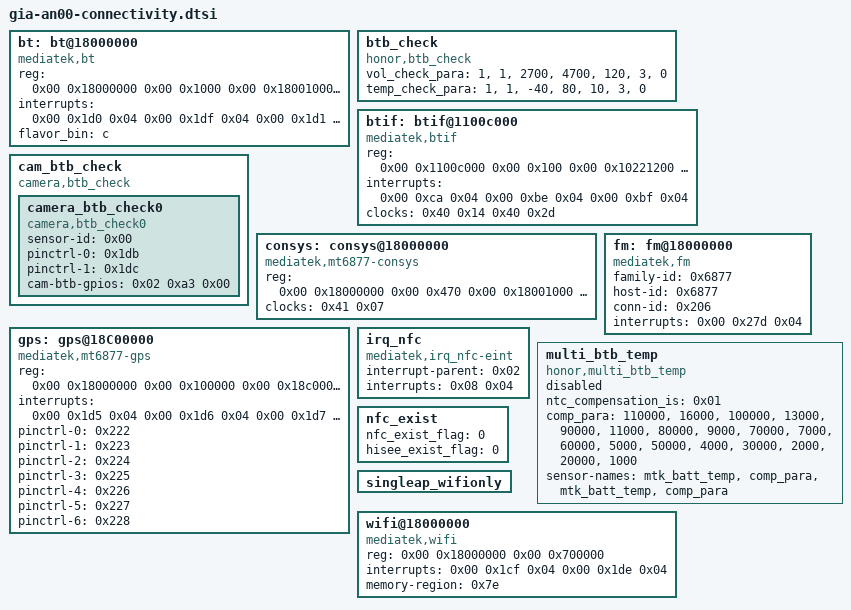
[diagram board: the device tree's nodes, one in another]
// SPDX-License-Identifier: GPL-2.0
/*
 * HONOR GIA-AN00 / MT6877V/ZA 设备树分片
 * 由实机反编译 device.dts 自动还原，节点内容保持原样
 */

/* 12 个顶层节点 */

	bt: bt@18000000 {
			compatible = "mediatek,bt";
			reg = <0x00 0x18000000 0x00 0x1000 0x00 0x18001000 0x00 0x1000 0x00 0x18050000 0x00 0x1000 0x00 0x18060000 0x00 0x1000 0x00 0x18800000 0x00 0x1000 0x00 0x18812000 0x00 0x1000 0x00 0x10001000 0x00 0x1000>;
			interrupts = <0x00 0x1d0 0x04 0x00 0x1df 0x04 0x00 0x1d1 0x04>;
			flavor_bin = "c";
			phandle = <0x34>;
		};

	btb_check: btb_check {
			compatible = "honor,btb_check";
			status = "ok";
			phandle = <0xd0>;
			vol_check_para = "1", "1", "2700", "4700", "120", "3", "0";
			temp_check_para = "1", "1", "-40", "80", "10", "3", "0";
		};

	btif: btif@1100c000 {
			compatible = "mediatek,btif";
			reg = <0x00 0x1100c000 0x00 0x100 0x00 0x10221200 0x00 0x80 0x00 0x10221280 0x00 0x80>;
			interrupts = <0x00 0xca 0x04 0x00 0xbe 0x04 0x00 0xbf 0x04>;
			clocks = <0x40 0x14 0x40 0x2d>;
			clock-names = "btifc", "apdmac";
			phandle = <0x33>;
		};

	cam_btb_check: cam_btb_check {
			compatible = "camera,btb_check";
			phandle = <0x159>;
	
			camera_btb_check0 {
				compatible = "camera,btb_check0";
				sensor-id = <0x00>;
				pinctrl-names = "cam_btb_default", "cam_btb_suspend";
				pinctrl-0 = <0x1db>;
				pinctrl-1 = <0x1dc>;
				cam-btb-gpios = <0x02 0xa3 0x00>;
				status = "ok";
			};
		};

	consys: consys@18000000 {
			compatible = "mediatek,mt6877-consys";
			reg = <0x00 0x18000000 0x00 0x470 0x00 0x18001000 0x00 0x658 0x00 0x18009000 0x00 0xa08 0x00 0x1800e000 0x00 0x3d8 0x00 0x18060000 0x00 0x460 0x00 0x10001000 0x00 0xfb8 0x00 0x10005000 0x00 0x718 0x00 0x10006000 0x00 0xfb0 0x00 0x10007000 0x00 0x51c 0x00 0x18005000 0x00 0x204 0x00 0x18052800 0x00 0x1000 0x00 0x18003000 0x00 0x128 0x00 0x18070000 0x00 0x8004 0x00 0x18004000 0x00 0x22c 0x00 0x11ea0000 0x00 0xa14 0x00 0x18002000 0x00 0x2c 0x00 0x1802e000 0x00 0x4c>;
			clocks = <0x41 0x07>;
			clock-names = "conn";
			phandle = <0x17c>;
		};

	fm: fm@18000000 {
			compatible = "mediatek,fm";
			family-id = <0x6877>;
			host-id = <0x6877>;
			conn-id = <0x206>;
			interrupts = <0x00 0x27d 0x04>;
			phandle = <0x17f>;
		};

	gps: gps@18C00000 {
			compatible = "mediatek,mt6877-gps";
			reg = <0x00 0x18000000 0x00 0x100000 0x00 0x18c00000 0x00 0x100000 0x00 0x10003304 0x00 0x04 0x00 0x1001c018 0x00 0x0c>;
			reg-names = "conn_infra_base", "conn_gps_base", "status_dummy_cr", "tia_gps";
			interrupts = <0x00 0x1d5 0x04 0x00 0x1d6 0x04 0x00 0x1d7 0x04 0x00 0x1d8 0x04 0x00 0x1d9 0x04 0x00 0x1da 0x04 0x00 0x1db 0x04>;
			phandle = <0x185>;
			pinctrl-names = "default", "gps_l1_lna_disable", "gps_l1_lna_dsp_ctrl", "gps_l1_lna_enable", "gps_l5_lna_disable", "gps_l5_lna_dsp_ctrl", "gps_l5_lna_enable";
			pinctrl-0 = <0x222>;
			pinctrl-1 = <0x223>;
			pinctrl-2 = <0x224>;
			pinctrl-3 = <0x225>;
			pinctrl-4 = <0x226>;
			pinctrl-5 = <0x227>;
			pinctrl-6 = <0x228>;
			status = "okay";
		};

	irq_nfc: irq_nfc {
			compatible = "mediatek,irq_nfc-eint";
			phandle = <0x134>;
			interrupt-parent = <0x02>;
			interrupts = <0x08 0x04>;
			status = "okay";
		};

	multi_btb_temp: multi_btb_temp {
			compatible = "honor,multi_btb_temp";
			status = "disabled";
			phandle = <0x103>;
			ntc_compensation_is = <0x01>;
			comp_para = "110000", "16000", "100000", "13000", "90000", "11000", "80000", "9000", "70000", "7000", "60000", "5000", "50000", "4000", "30000", "2000", "20000", "1000";
			sensor-names = "mtk_batt_temp", "comp_para", "mtk_batt_temp", "comp_para";
		};

	nfc_exist: nfc_exist {
			nfc_exist_flag = "0";
			hisee_exist_flag = "0";
			status = "ok";
			phandle = <0x133>;
		};

	singleap_wifionly: singleap_wifionly {
			phandle = <0xe1>;
		};

	wifi@18000000 {
			compatible = "mediatek,wifi";
			reg = <0x00 0x18000000 0x00 0x700000>;
			interrupts = <0x00 0x1cf 0x04 0x00 0x1de 0x04>;
			memory-region = <0x7e>;
		};

